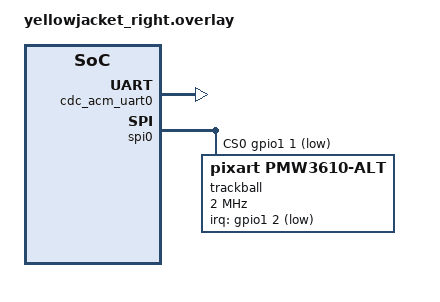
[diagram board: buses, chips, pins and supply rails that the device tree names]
/*
 * Copyright (c) 2020 The ZMK Contributors
 *
 * SPDX-License-Identifier: MIT
 */

#include "yellowjacket.dtsi"
#include <zephyr/dt-bindings/input/input-event-codes.h>

&default_transform {
    col-offset = <16>;
};

/* USB CDC ACM for logging */
&zephyr_udc0 {
    cdc_acm_uart0: cdc_acm_uart0 {
        compatible = "zephyr,cdc-acm-uart";
    };
};

/ {
    chosen {
        zephyr,console = &cdc_acm_uart0;
    };
};

&spi0 {
    status = "okay";
    compatible = "nordic,nrf-spim";
    pinctrl-0 = <&spi0_default>;
    pinctrl-1 = <&spi0_sleep>;
    pinctrl-names = "default", "sleep";
    cs-gpios = <&gpio1 1 GPIO_ACTIVE_LOW>;

    trackball: trackball@0 {
        status = "okay";
        compatible = "pixart,pmw3610-alt";
        reg = <0>;
        spi-max-frequency = <2000000>;
        irq-gpios = <&gpio1 2 (GPIO_ACTIVE_LOW | GPIO_PULL_UP)>;
        cpi = <600>;
        evt-type = <INPUT_EV_REL>;
        x-input-code = <INPUT_REL_X>;
        y-input-code = <INPUT_REL_Y>;
    };
};

/ {
    trackball_listener {
        compatible = "zmk,input-listener";
        device = <&trackball>;
    };
};
